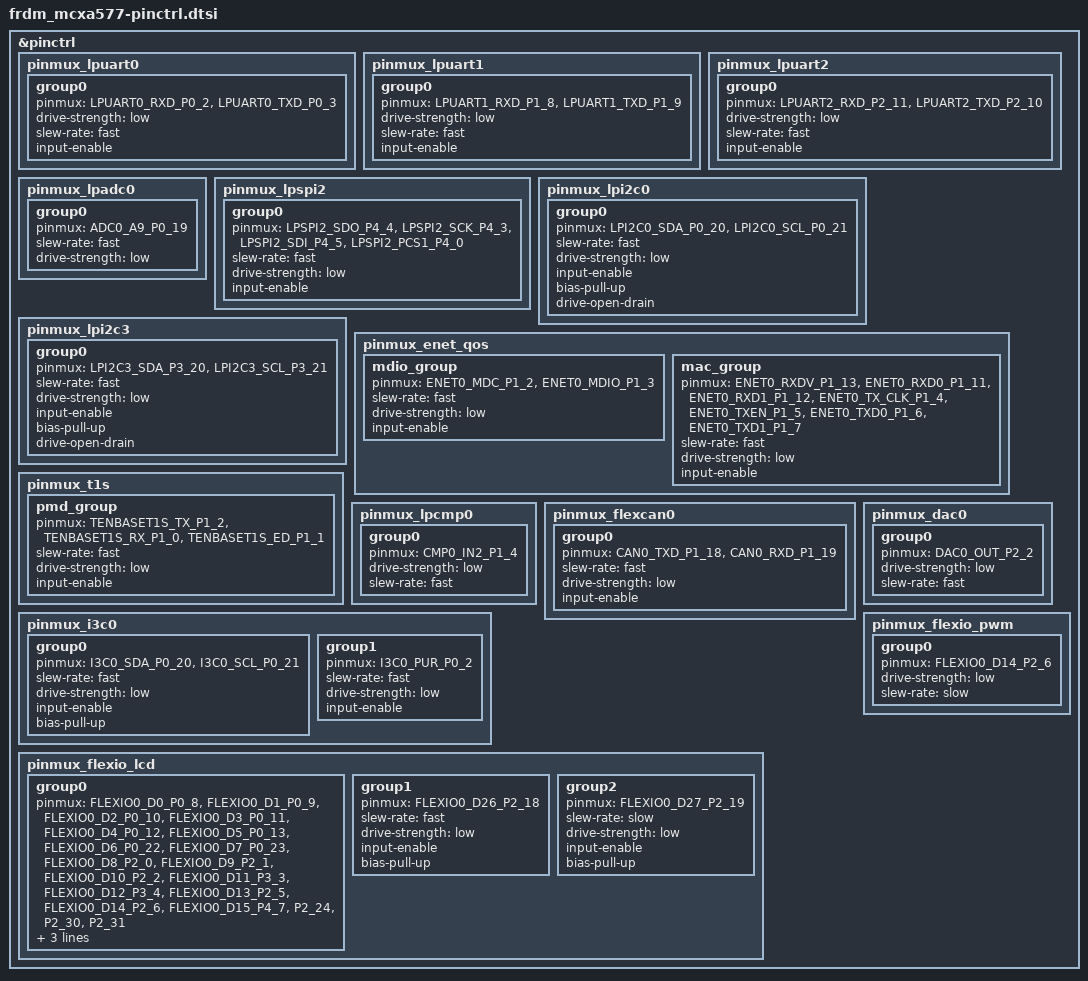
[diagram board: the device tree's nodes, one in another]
/*
 * Copyright 2025-2026 NXP
 * SPDX-License-Identifier: Apache-2.0
 */

#include <nxp/mcx/MCXA577VPN-pinctrl.h>

&pinctrl {
	pinmux_lpuart0: pinmux_lpuart0 {
		group0 {
			pinmux = <LPUART0_RXD_P0_2>,
				 <LPUART0_TXD_P0_3>;
			drive-strength = "low";
			slew-rate = "fast";
			input-enable;
		};
	};

	pinmux_lpuart1: pinmux_lpuart1 {
		group0 {
			pinmux = <LPUART1_RXD_P1_8>,
				 <LPUART1_TXD_P1_9>;
			drive-strength = "low";
			slew-rate = "fast";
			input-enable;
		};
	};

	pinmux_lpuart2: pinmux_lpuart2 {
		group0 {
			pinmux = <LPUART2_RXD_P2_11>,
				 <LPUART2_TXD_P2_10>;
			drive-strength = "low";
			slew-rate = "fast";
			input-enable;
		};
	};

	pinmux_lpadc0: pinmux_lpadc0 {
		group0 {
			pinmux = <ADC0_A9_P0_19>;
			slew-rate = "fast";
			drive-strength = "low";
		};
	};

	pinmux_lpspi2: pinmux_lpspi2 {
		group0 {
			pinmux = <LPSPI2_SDO_P4_4>,
				 <LPSPI2_SCK_P4_3>,
				 <LPSPI2_SDI_P4_5>,
				 <LPSPI2_PCS1_P4_0>;
			slew-rate = "fast";
			drive-strength = "low";
			input-enable;
		};
	};

	pinmux_lpi2c0: pinmux_lpi2c0 {
		group0 {
			pinmux = <LPI2C0_SDA_P0_20>,
				 <LPI2C0_SCL_P0_21>;
			slew-rate = "fast";
			drive-strength = "low";
			input-enable;
			bias-pull-up;
			drive-open-drain;
		};
	};

	pinmux_lpi2c3: pinmux_lpi2c3 {
		group0 {
			pinmux = <LPI2C3_SDA_P3_20>,
				 <LPI2C3_SCL_P3_21>;
			slew-rate = "fast";
			drive-strength = "low";
			input-enable;
			bias-pull-up;
			drive-open-drain;
		};
	};

	pinmux_enet_qos: pinmux_enet_qos {
		mdio_group {
			pinmux = <ENET0_MDC_P1_2>,
				 <ENET0_MDIO_P1_3>;
			slew-rate = "fast";
			drive-strength = "low";
			input-enable;
		};

		mac_group {
			pinmux = <ENET0_RXDV_P1_13>,
				 <ENET0_RXD0_P1_11>,
				 <ENET0_RXD1_P1_12>,
				 <ENET0_TX_CLK_P1_4>,
				 <ENET0_TXEN_P1_5>,
				 <ENET0_TXD0_P1_6>,
				 <ENET0_TXD1_P1_7>;
			slew-rate = "fast";
			drive-strength = "low";
			input-enable;
		};
	};

	pinmux_t1s: pinmux_t1s {
		pmd_group {
			pinmux = <TENBASET1S_TX_P1_2>,
				 <TENBASET1S_RX_P1_0>,
				 <TENBASET1S_ED_P1_1>;
			slew-rate = "fast";
			drive-strength = "low";
			input-enable;
		};
	};

	pinmux_lpcmp0: pinmux_lpcmp0 {
		group0 {
			pinmux = <CMP0_IN2_P1_4>;
			drive-strength = "low";
			slew-rate = "fast";
		};
	};

	pinmux_flexcan0: pinmux_flexcan0 {
		group0 {
			pinmux = <CAN0_TXD_P1_18>,
				 <CAN0_RXD_P1_19>;
			slew-rate = "fast";
			drive-strength = "low";
			input-enable;
		};
	};

	pinmux_dac0: pinmux_dac0 {
		group0 {
			pinmux = <DAC0_OUT_P2_2>;
			drive-strength = "low";
			slew-rate = "fast";
		};
	};

	pinmux_i3c0: pinmux_i3c0 {
		group0 {
			pinmux = <I3C0_SDA_P0_20>,
				 <I3C0_SCL_P0_21>;
			slew-rate = "fast";
			drive-strength = "low";
			input-enable;
			bias-pull-up;
		};

		group1 {
			pinmux = <I3C0_PUR_P0_2>;
			slew-rate = "fast";
			drive-strength = "low";
			input-enable;
		};
	};

	pinmux_flexio_lcd: pinmux_flexio_lcd {
		group0 {
			pinmux = <FLEXIO0_D0_P0_8>,
				 <FLEXIO0_D1_P0_9>,
				 <FLEXIO0_D2_P0_10>,
				 <FLEXIO0_D3_P0_11>,
				 <FLEXIO0_D4_P0_12>,
				 <FLEXIO0_D5_P0_13>,
				 <FLEXIO0_D6_P0_22>,
				 <FLEXIO0_D7_P0_23>,
				 <FLEXIO0_D8_P2_0>,
				 <FLEXIO0_D9_P2_1>,
				 <FLEXIO0_D10_P2_2>,
				 <FLEXIO0_D11_P3_3>,
				 <FLEXIO0_D12_P3_4>,
				 <FLEXIO0_D13_P2_5>,
				 <FLEXIO0_D14_P2_6>,
				 <FLEXIO0_D15_P4_7>,
				 <P2_24>,
				 <P2_30>,
				 <P2_31>;
			slew-rate = "fast";
			drive-strength = "low";
			input-enable;
		};

		group1 {
			pinmux = <FLEXIO0_D26_P2_18>;
			slew-rate = "fast";
			drive-strength = "low";
			input-enable;
			bias-pull-up;
		};

		group2 {
			pinmux = <FLEXIO0_D27_P2_19>;
			slew-rate = "slow";
			drive-strength = "low";
			input-enable;
			bias-pull-up;
		};
	};

	pinmux_flexio_pwm: pinmux_flexio_pwm {
		group0 {
			pinmux = <FLEXIO0_D14_P2_6>;
			drive-strength = "low";
			slew-rate = "slow";
		};
	};
};
